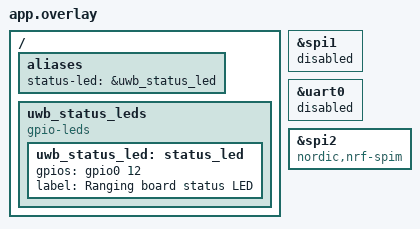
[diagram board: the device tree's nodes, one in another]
/ {
	aliases {
		status-led = &uwb_status_led;
	};

	uwb_status_leds {
		compatible = "gpio-leds";

		uwb_status_led: status_led {
			gpios = <&gpio0 12 GPIO_ACTIVE_HIGH>;
			label = "Ranging board status LED";
		};
	};
};

/* External DWM1001C SPI pins are connected to the ESP32-C3 on this PCB. */
&spi1 {
	status = "disabled";
};

/* Anchor firmware does not exchange telemetry with the ESP32-C3. */
&uart0 {
	status = "disabled";
};

/*
 * DW1000 bus: EasyDMA SPIM instead of the board's per-byte-interrupt SPI.
 * In the v3 burst the slot-0 anchor must read the POLL and schedule its
 * RESP within the base delay (~0.8 ms). uwb_platform_spi_xfer() never
 * issues a 1-byte transfer (nRF52832 anomaly 58).
 */
&spi2 {
	compatible = "nordic,nrf-spim";
};
